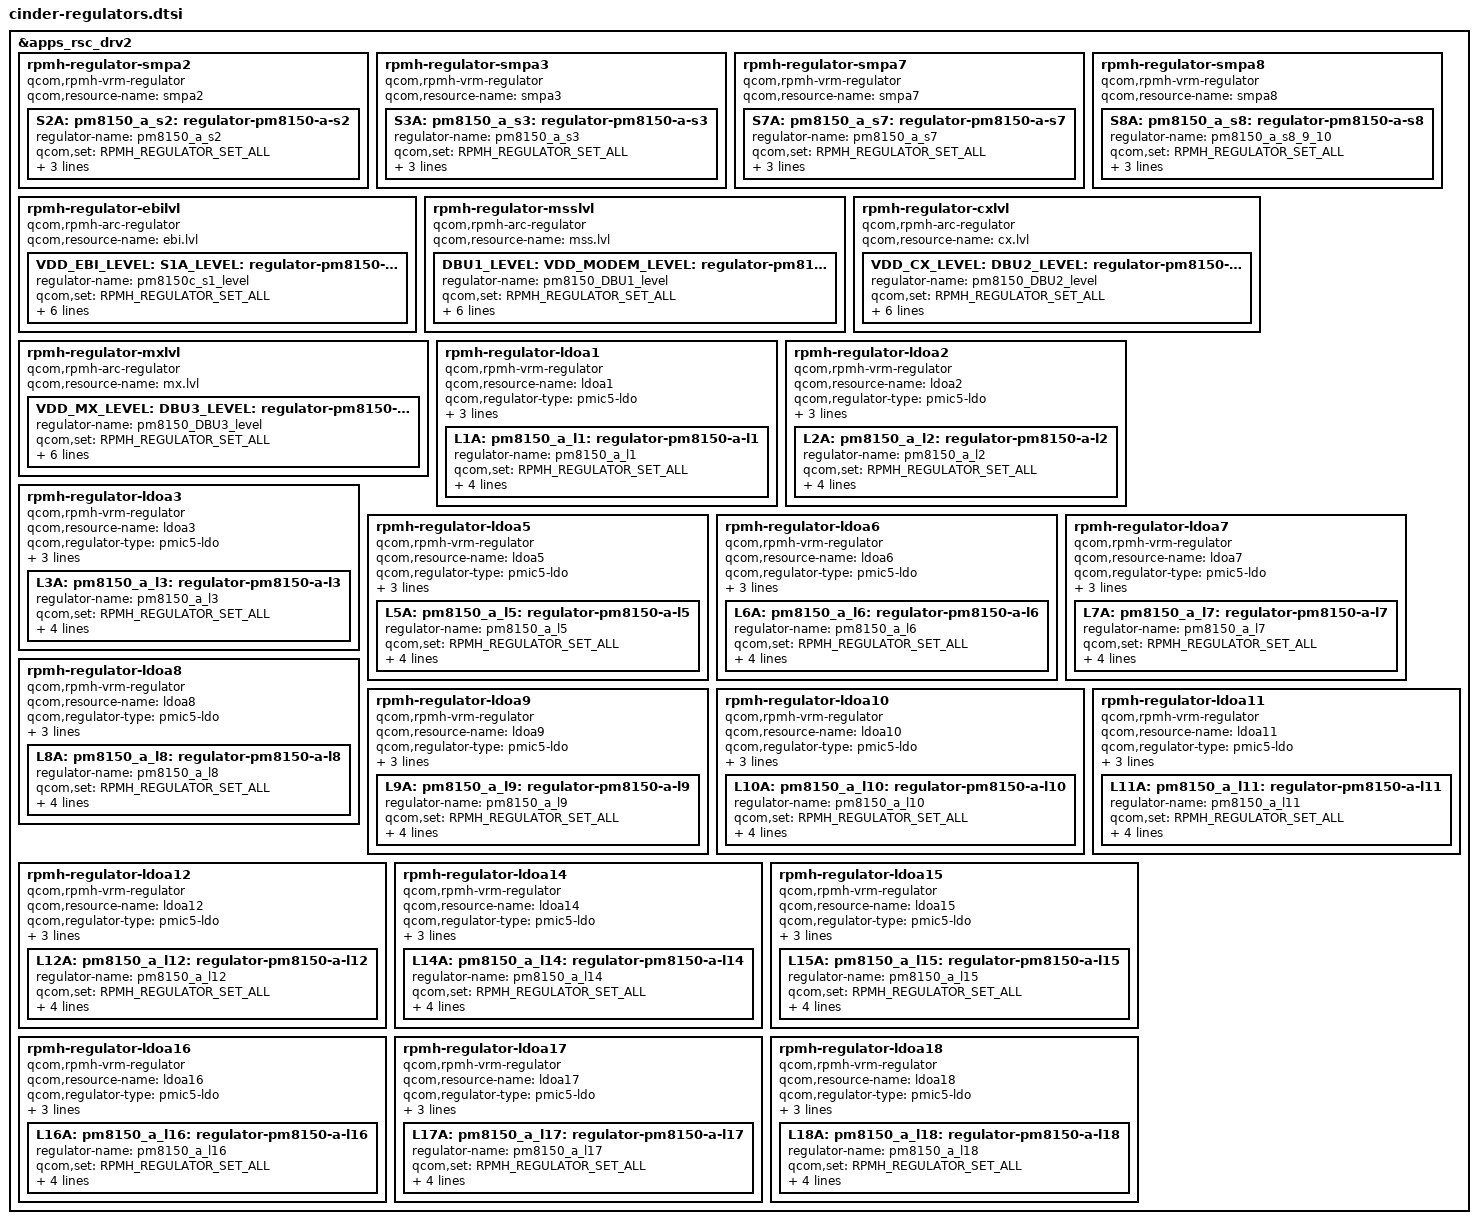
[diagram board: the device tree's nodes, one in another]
#include <dt-bindings/regulator/qcom,rpmh-regulator-levels.h>

&apps_rsc_drv2 {
	/* RPMh regulators: */

	rpmh-regulator-smpa2 {
		compatible = "qcom,rpmh-vrm-regulator";
		qcom,resource-name = "smpa2";
		S2A: pm8150_a_s2: regulator-pm8150-a-s2 {
			regulator-name = "pm8150_a_s2";
			qcom,set = <RPMH_REGULATOR_SET_ALL>;
			regulator-min-microvolt = <320000>;
			regulator-max-microvolt = <570000>;
			qcom,init-voltage = <500000>;
		};
	};

	rpmh-regulator-smpa3 {
		compatible = "qcom,rpmh-vrm-regulator";
		qcom,resource-name = "smpa3";
		S3A: pm8150_a_s3: regulator-pm8150-a-s3 {
			regulator-name = "pm8150_a_s3";
			qcom,set = <RPMH_REGULATOR_SET_ALL>;
			regulator-min-microvolt = <950000>;
			regulator-max-microvolt = <1170000>;
			qcom,init-voltage = <1084000>;
		};
	};

	rpmh-regulator-smpa7 {
		compatible = "qcom,rpmh-vrm-regulator";
		qcom,resource-name = "smpa7";
		S7A: pm8150_a_s7: regulator-pm8150-a-s7 {
			regulator-name = "pm8150_a_s7";
			qcom,set = <RPMH_REGULATOR_SET_ALL>;
			regulator-min-microvolt = <1200000>;
			regulator-max-microvolt = <1200000>;
			qcom,init-voltage = <1200000>;
		};
	};

	/*SMPS8_9_10*/
	rpmh-regulator-smpa8 {
		compatible = "qcom,rpmh-vrm-regulator";
		qcom,resource-name = "smpa8";
		S8A: pm8150_a_s8: regulator-pm8150-a-s8 {
			regulator-name = "pm8150_a_s8_9_10";
			qcom,set = <RPMH_REGULATOR_SET_ALL>;
			regulator-min-microvolt = <750000>;
			regulator-max-microvolt = <750000>;
			qcom,init-voltage = <750000>;
		};
	};

	rpmh-regulator-ebilvl {
		compatible = "qcom,rpmh-arc-regulator";
		qcom,resource-name = "ebi.lvl";
		VDD_EBI_LEVEL: S1A_LEVEL:
		pm8150_s1_level: regulator-pm8150-s1-level {
			regulator-name = "pm8150c_s1_level";
			qcom,set = <RPMH_REGULATOR_SET_ALL>;
			regulator-min-microvolt =
				<RPMH_REGULATOR_LEVEL_RETENTION>;
			regulator-max-microvolt =
				<RPMH_REGULATOR_LEVEL_MAX>;
			qcom,init-voltage-level =
				<RPMH_REGULATOR_LEVEL_RETENTION>;
		};
	};

	/* PM8150 PMIC_MSS_EN  = VDD_MODEM supply */
	rpmh-regulator-msslvl {
		compatible = "qcom,rpmh-arc-regulator";
		qcom,resource-name = "mss.lvl";
		DBU1_LEVEL: VDD_MODEM_LEVEL:
		pm8150_DBU1_level: regulator-pm8150-DBU1-level {
			regulator-name = "pm8150_DBU1_level";
			qcom,set = <RPMH_REGULATOR_SET_ALL>;
			regulator-min-microvolt
				= <RPMH_REGULATOR_LEVEL_RETENTION>;
			regulator-max-microvolt
				= <RPMH_REGULATOR_LEVEL_MAX>;
			qcom,init-voltage-level
				= <RPMH_REGULATOR_LEVEL_RETENTION>;
		};
	};

	rpmh-regulator-cxlvl {
		compatible = "qcom,rpmh-arc-regulator";
		qcom,resource-name = "cx.lvl";

		VDD_CX_LEVEL: DBU2_LEVEL:
		pm8150_DBU2_level: regulator-pm8150-DBU2-level {
			regulator-name = "pm8150_DBU2_level";
			qcom,set = <RPMH_REGULATOR_SET_ALL>;
			regulator-min-microvolt
				= <RPMH_REGULATOR_LEVEL_RETENTION>;
			regulator-max-microvolt
				= <RPMH_REGULATOR_LEVEL_MAX>;
			qcom,init-voltage-level
				= <RPMH_REGULATOR_LEVEL_RETENTION>;
		};
	};

	rpmh-regulator-mxlvl {
		compatible = "qcom,rpmh-arc-regulator";
		qcom,resource-name = "mx.lvl";

		VDD_MX_LEVEL: DBU3_LEVEL:
		pm8150_DBU3_level: regulator-pm8150-DBU3-level {
			regulator-name = "pm8150_DBU3_level";
			qcom,set = <RPMH_REGULATOR_SET_ALL>;
			regulator-min-microvolt
				= <RPMH_REGULATOR_LEVEL_RETENTION>;
			regulator-max-microvolt
				= <RPMH_REGULATOR_LEVEL_MAX>;
			qcom,init-voltage-level
				= <RPMH_REGULATOR_LEVEL_RETENTION>;
		};
	};

	rpmh-regulator-ldoa1 {
		compatible = "qcom,rpmh-vrm-regulator";
		qcom,resource-name = "ldoa1";
		qcom,regulator-type = "pmic5-ldo";
		qcom,supported-modes =
			<RPMH_REGULATOR_MODE_LPM
			 RPMH_REGULATOR_MODE_HPM>;
		qcom,mode-threshold-currents = <0 30000>;
		L1A: pm8150_a_l1: regulator-pm8150-a-l1 {
			regulator-name = "pm8150_a_l1";
			qcom,set = <RPMH_REGULATOR_SET_ALL>;
			regulator-min-microvolt = <312000>;
			regulator-max-microvolt = <1304000>;
			qcom,init-voltage = <912000>;
			qcom,init-mode = <RPMH_REGULATOR_MODE_LPM>;
		};
	};

	rpmh-regulator-ldoa2 {
		compatible = "qcom,rpmh-vrm-regulator";
		qcom,resource-name = "ldoa2";
		qcom,regulator-type = "pmic5-ldo";
		qcom,supported-modes =
			<RPMH_REGULATOR_MODE_LPM
			 RPMH_REGULATOR_MODE_HPM>;
		qcom,mode-threshold-currents = <0 10000>;
		L2A: pm8150_a_l2: regulator-pm8150-a-l2 {
			regulator-name = "pm8150_a_l2";
			qcom,set = <RPMH_REGULATOR_SET_ALL>;
			regulator-min-microvolt = <2970000>;
			regulator-max-microvolt = <3300000>;
			qcom,init-voltage = <3300000>;
			qcom,init-mode = <RPMH_REGULATOR_MODE_LPM>;
		};
	};

	rpmh-regulator-ldoa3 {
		compatible = "qcom,rpmh-vrm-regulator";
		qcom,resource-name = "ldoa3";
		qcom,regulator-type = "pmic5-ldo";
		qcom,supported-modes =
			<RPMH_REGULATOR_MODE_LPM
			 RPMH_REGULATOR_MODE_HPM>;
		qcom,mode-threshold-currents = <0 30000>;
		L3A: pm8150_a_l3: regulator-pm8150-a-l3 {
			regulator-name = "pm8150_a_l3";
			qcom,set = <RPMH_REGULATOR_SET_ALL>;
			regulator-min-microvolt = <920000>;
			regulator-max-microvolt = <1260000>;
			qcom,init-voltage = <1200000>;
			qcom,init-mode = <RPMH_REGULATOR_MODE_LPM>;
		};
	};

	rpmh-regulator-ldoa5 {
		compatible = "qcom,rpmh-vrm-regulator";
		qcom,resource-name = "ldoa5";
		qcom,regulator-type = "pmic5-ldo";
		qcom,supported-modes =
			<RPMH_REGULATOR_MODE_LPM
			 RPMH_REGULATOR_MODE_HPM>;
		qcom,mode-threshold-currents = <0 30000>;
		L5A: pm8150_a_l5: regulator-pm8150-a-l5 {
			regulator-name = "pm8150_a_l5";
			qcom,set = <RPMH_REGULATOR_SET_ALL>;
			regulator-min-microvolt = <312000>;
			regulator-max-microvolt = <1304000>;
			qcom,init-voltage = <800000>;
			qcom,init-mode = <RPMH_REGULATOR_MODE_LPM>;
		};
	};

	rpmh-regulator-ldoa6 {
		compatible = "qcom,rpmh-vrm-regulator";
		qcom,resource-name = "ldoa6";
		qcom,regulator-type = "pmic5-ldo";
		qcom,supported-modes =
			<RPMH_REGULATOR_MODE_LPM
			 RPMH_REGULATOR_MODE_HPM>;
		qcom,mode-threshold-currents = <0 30000>;
		L6A: pm8150_a_l6: regulator-pm8150-a-l6 {
			regulator-name = "pm8150_a_l6";
			qcom,set = <RPMH_REGULATOR_SET_ALL>;
			regulator-min-microvolt = <880000>;
			regulator-max-microvolt = <950000>;
			qcom,init-voltage = <912000>;
			qcom,init-mode = <RPMH_REGULATOR_MODE_LPM>;
		};
	};

	rpmh-regulator-ldoa7 {
		compatible = "qcom,rpmh-vrm-regulator";
		qcom,resource-name = "ldoa7";
		qcom,regulator-type = "pmic5-ldo";
		qcom,supported-modes =
			<RPMH_REGULATOR_MODE_LPM
			 RPMH_REGULATOR_MODE_HPM>;
		qcom,mode-threshold-currents = <0 10000>;
		L7A: pm8150_a_l7: regulator-pm8150-a-l7 {
			regulator-name = "pm8150_a_l7";
			qcom,set = <RPMH_REGULATOR_SET_ALL>;
			regulator-min-microvolt = <1650000>;
			regulator-max-microvolt = <2000000>;
			qcom,init-voltage = <1800000>;
			qcom,init-mode = <RPMH_REGULATOR_MODE_LPM>;
		};
	};

	rpmh-regulator-ldoa8 {
		compatible = "qcom,rpmh-vrm-regulator";
		qcom,resource-name = "ldoa8";
		qcom,regulator-type = "pmic5-ldo";
		qcom,supported-modes =
			<RPMH_REGULATOR_MODE_LPM
			 RPMH_REGULATOR_MODE_HPM>;
		qcom,mode-threshold-currents = <0 30000>;
		L8A: pm8150_a_l8: regulator-pm8150-a-l8 {
			regulator-name = "pm8150_a_l8";
			qcom,set = <RPMH_REGULATOR_SET_ALL>;
			regulator-min-microvolt = <888000>;
			regulator-max-microvolt = <925000>;
			qcom,init-voltage = <912000>;
			qcom,init-mode = <RPMH_REGULATOR_MODE_LPM>;
		};
	};

	rpmh-regulator-ldoa9 {
		compatible = "qcom,rpmh-vrm-regulator";
		qcom,resource-name = "ldoa9";
		qcom,regulator-type = "pmic5-ldo";
		qcom,supported-modes =
			<RPMH_REGULATOR_MODE_LPM
			 RPMH_REGULATOR_MODE_HPM>;
		qcom,mode-threshold-currents = <0 30000>;
		L9A: pm8150_a_l9: regulator-pm8150-a-l9 {
			regulator-name = "pm8150_a_l9";
			qcom,set = <RPMH_REGULATOR_SET_ALL>;
			regulator-min-microvolt = <312000>;
			regulator-max-microvolt = <1304000>;
			qcom,init-voltage = <912000>;
			qcom,init-mode = <RPMH_REGULATOR_MODE_LPM>;
		};
	};

	rpmh-regulator-ldoa10 {
		compatible = "qcom,rpmh-vrm-regulator";
		qcom,resource-name = "ldoa10";
		qcom,regulator-type = "pmic5-ldo";
		qcom,supported-modes =
			<RPMH_REGULATOR_MODE_LPM
			 RPMH_REGULATOR_MODE_HPM>;
		qcom,mode-threshold-currents = <0 10000>;
		L10A: pm8150_a_l10: regulator-pm8150-a-l10 {
			regulator-name = "pm8150_a_l10";
			qcom,set = <RPMH_REGULATOR_SET_ALL>;
			regulator-min-microvolt = <2700000>;
			regulator-max-microvolt = <3544000>;
			qcom,init-voltage = <2952000>;
			qcom,init-mode = <RPMH_REGULATOR_MODE_LPM>;
		};
	};

	rpmh-regulator-ldoa11 {
		compatible = "qcom,rpmh-vrm-regulator";
		qcom,resource-name = "ldoa11";
		qcom,regulator-type = "pmic5-ldo";
		qcom,supported-modes =
			<RPMH_REGULATOR_MODE_LPM
			 RPMH_REGULATOR_MODE_HPM>;
		qcom,mode-threshold-currents = <0 30000>;
		L11A: pm8150_a_l11: regulator-pm8150-a-l11 {
			regulator-name = "pm8150_a_l11";
			qcom,set = <RPMH_REGULATOR_SET_ALL>;
			regulator-min-microvolt = <800000>;
			regulator-max-microvolt = <1000000>;
			qcom,init-voltage = <912000>;
			qcom,init-mode = <RPMH_REGULATOR_MODE_LPM>;
		};
	};

	rpmh-regulator-ldoa12 {
		compatible = "qcom,rpmh-vrm-regulator";
		qcom,resource-name = "ldoa12";
		qcom,regulator-type = "pmic5-ldo";
		qcom,supported-modes =
			<RPMH_REGULATOR_MODE_LPM
			 RPMH_REGULATOR_MODE_HPM>;
		qcom,mode-threshold-currents = <0 10000>;
		L12A: pm8150_a_l12: regulator-pm8150-a-l12 {
			regulator-name = "pm8150_a_l12";
			qcom,set = <RPMH_REGULATOR_SET_ALL>;
			regulator-min-microvolt = <1504000>;
			regulator-max-microvolt = <1504000>;
			qcom,init-voltage = <1504000>;
			qcom,init-mode = <RPMH_REGULATOR_MODE_LPM>;
		};
	};

	rpmh-regulator-ldoa14 {
		compatible = "qcom,rpmh-vrm-regulator";
		qcom,resource-name = "ldoa14";
		qcom,regulator-type = "pmic5-ldo";
		qcom,supported-modes =
			<RPMH_REGULATOR_MODE_LPM
			 RPMH_REGULATOR_MODE_HPM>;
		qcom,mode-threshold-currents = <0 10000>;
		L14A: pm8150_a_l14: regulator-pm8150-a-l14 {
			regulator-name = "pm8150_a_l14";
			qcom,set = <RPMH_REGULATOR_SET_ALL>;
			regulator-min-microvolt = <1650000>;
			regulator-max-microvolt = <1950000>;
			qcom,init-voltage = <1800000>;
			qcom,init-mode = <RPMH_REGULATOR_MODE_LPM>;
		};
	};

	rpmh-regulator-ldoa15 {
		compatible = "qcom,rpmh-vrm-regulator";
		qcom,resource-name = "ldoa15";
		qcom,regulator-type = "pmic5-ldo";
		qcom,supported-modes =
			<RPMH_REGULATOR_MODE_LPM
			 RPMH_REGULATOR_MODE_HPM>;
		qcom,mode-threshold-currents = <0 10000>;
		L15A: pm8150_a_l15: regulator-pm8150-a-l15 {
			regulator-name = "pm8150_a_l15";
			qcom,set = <RPMH_REGULATOR_SET_ALL>;
			regulator-min-microvolt = <1504000>;
			regulator-max-microvolt = <2000000>;
			qcom,init-voltage = <1800000>;
			qcom,init-mode = <RPMH_REGULATOR_MODE_LPM>;
		};
	};

	rpmh-regulator-ldoa16 {
		compatible = "qcom,rpmh-vrm-regulator";
		qcom,resource-name = "ldoa16";
		qcom,regulator-type = "pmic5-ldo";
		qcom,supported-modes =
			<RPMH_REGULATOR_MODE_LPM
			 RPMH_REGULATOR_MODE_HPM>;
		qcom,mode-threshold-currents = <0 10000>;
		L16A: pm8150_a_l16: regulator-pm8150-a-l16 {
			regulator-name = "pm8150_a_l16";
			qcom,set = <RPMH_REGULATOR_SET_ALL>;
			regulator-min-microvolt = <1710000>;
			regulator-max-microvolt = <1890000>;
			qcom,init-voltage = <1701000>;
			qcom,init-mode = <RPMH_REGULATOR_MODE_LPM>;
		};
	};

	rpmh-regulator-ldoa17 {
		compatible = "qcom,rpmh-vrm-regulator";
		qcom,resource-name = "ldoa17";
		qcom,regulator-type = "pmic5-ldo";
		qcom,supported-modes =
			<RPMH_REGULATOR_MODE_LPM
			 RPMH_REGULATOR_MODE_HPM>;
		qcom,mode-threshold-currents = <0 10000>;
		L17A: pm8150_a_l17: regulator-pm8150-a-l17 {
			regulator-name = "pm8150_a_l17";
			qcom,set = <RPMH_REGULATOR_SET_ALL>;
			regulator-min-microvolt = <3000000>;
			regulator-max-microvolt = <3544000>;
			qcom,init-voltage = <3000000>;
			qcom,init-mode = <RPMH_REGULATOR_MODE_LPM>;
		};
	};

	rpmh-regulator-ldoa18 {
		compatible = "qcom,rpmh-vrm-regulator";
		qcom,resource-name = "ldoa18";
		qcom,regulator-type = "pmic5-ldo";
		qcom,supported-modes =
			<RPMH_REGULATOR_MODE_LPM
			 RPMH_REGULATOR_MODE_HPM>;
		qcom,mode-threshold-currents = <0 30000>;
		L18A: pm8150_a_l18: regulator-pm8150-a-l18 {
			regulator-name = "pm8150_a_l18";
			qcom,set = <RPMH_REGULATOR_SET_ALL>;
			regulator-min-microvolt = <312000>;
			regulator-max-microvolt = <1304000>;
			qcom,init-voltage = <1200000>;
			qcom,init-mode = <RPMH_REGULATOR_MODE_LPM>;
		};
	};
};
